AUTOSAR XML (schema 4.0)
package /AppComponents
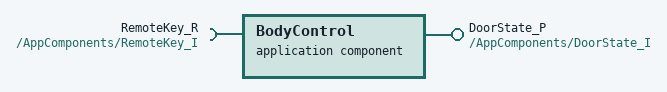
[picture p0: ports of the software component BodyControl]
  application sw component type BodyControl
    provide port DoorState_P: provided-interface=/AppComponents/DoorState_I
    require port RemoteKey_R: required-interface=/AppComponents/RemoteKey_I
